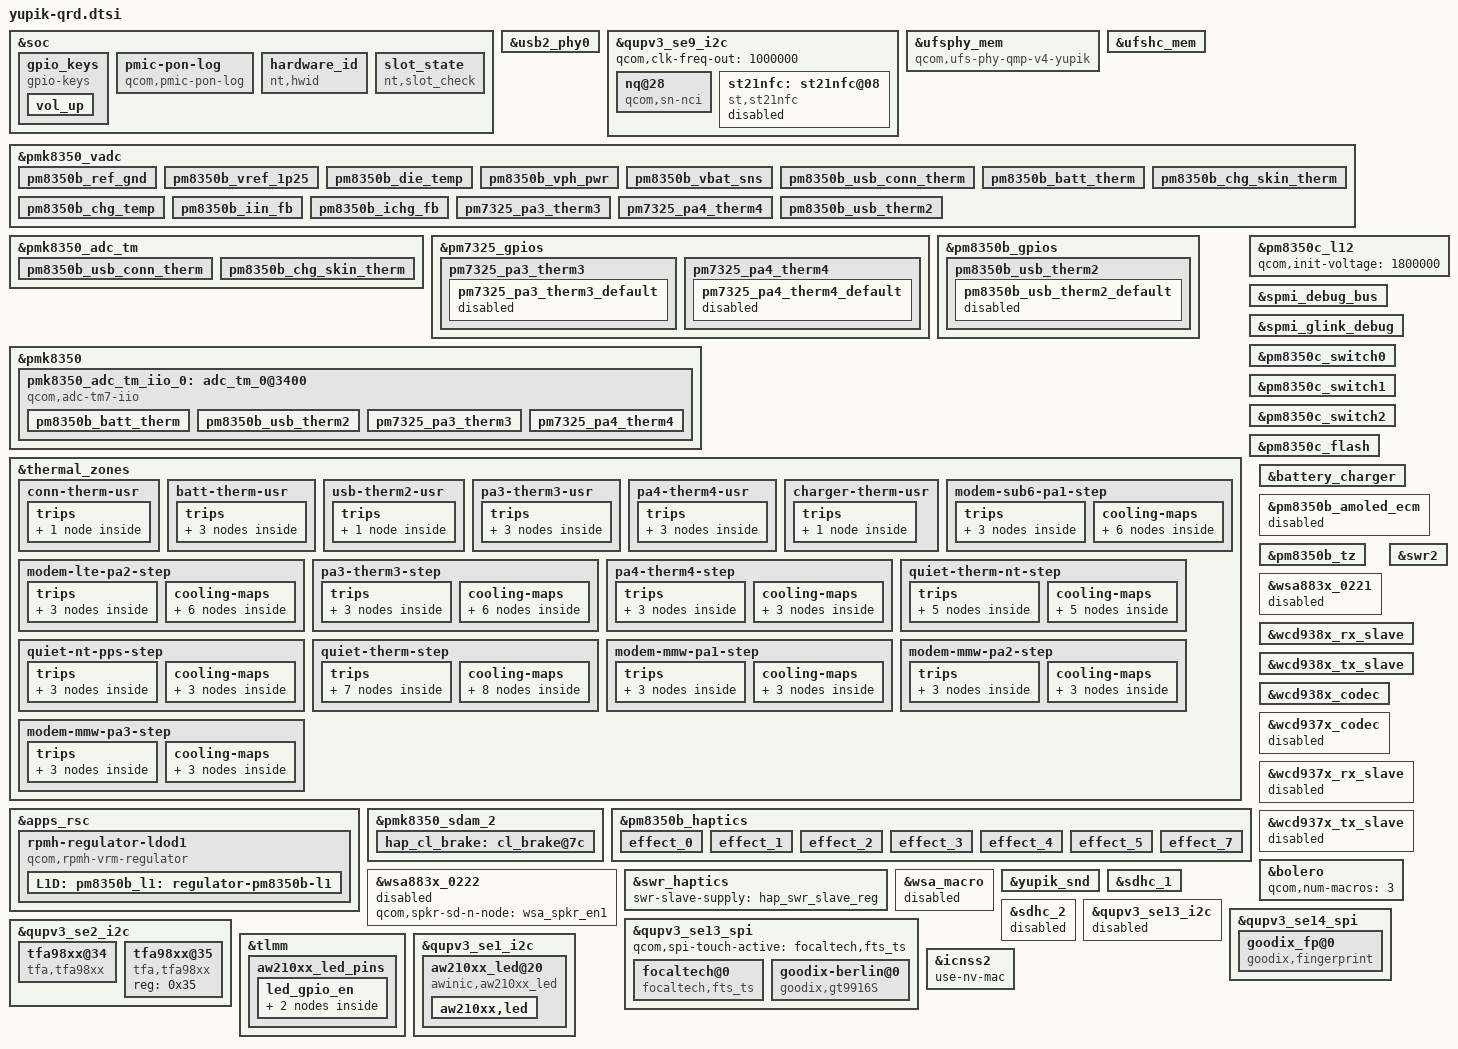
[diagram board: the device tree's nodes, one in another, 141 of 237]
#include <dt-bindings/gpio/gpio.h>
#include <dt-bindings/clock/qcom,rpmh.h>
#include <dt-bindings/regulator/qcom,rpmh-regulator-levels.h>
#include "yupik-pmic-overlay.dtsi"
#include "pm8350b.dtsi"
#include "yupik-audio-overlay.dtsi"
#include "yupik-thermal-overlay-qrd.dtsi"
#include "display/yupik-sde-display-qrd.dtsi"
//#include "camera/yupik-camera-sensor-qrd.dtsi"
#include "camera/abra-camera-sensor.dtsi"

&soc {
	gpio_keys {
		compatible = "gpio-keys";
		label = "gpio-keys";

		pinctrl-names = "default";
		pinctrl-0 = <&key_vol_up_default>;

		vol_up {
			label = "volume_up";
			gpios = <&pm7325_gpios 6 GPIO_ACTIVE_LOW>;
			linux,input-type = <1>;
			linux,code = <KEY_VOLUMEUP>;
			gpio-key,wakeup;
			debounce-interval = <15>;
			linux,can-disable;
		};
	};

	pmic-pon-log {
		compatible = "qcom,pmic-pon-log";
		nvmem = <&pmk8350_sdam_5>;
		nvmem-names = "pon_log";
	};
};

&usb2_phy0 {
	qcom,param-override-seq =
		<0xe6 0x6c	/* override_x0 */
		 0x0b 0x70	/* override_x1 */
		 0x14 0x74>;	/* override_x2 */
};

&qupv3_se9_i2c {
	status = "ok";
	qcom,clk-freq-out = <1000000>;
	#address-cells = <1>;
	#size-cells = <0>;
	nq@28 {
		compatible = "qcom,sn-nci";
		reg = <0x28>;
		qcom,sn-irq = <&tlmm 41 0x00>;
		qcom,sn-ven = <&tlmm 38 0x00>;
		qcom,sn-firm = <&tlmm 40 0x00>;
		qcom,sn-clkreq = <&tlmm 39 0x00>;
		qcom,sn-vdd-1p8-supply = <&L18B>;
		qcom,sn-vdd-1p8-voltage = <1800000 1800000>;
		qcom,sn-vdd-1p8-current = <157000>;
		interrupt-parent = <&tlmm>;
		interrupts = <41 0>;
		interrupt-names = "nfc_irq";
		pinctrl-names = "nfc_active", "nfc_suspend";
		pinctrl-0 = <&nfc_int_active &nfc_enable_active>;
		pinctrl-1 = <&nfc_int_suspend &nfc_enable_suspend>;
		status = "okay";
	};
};

&ufsphy_mem {
	compatible = "qcom,ufs-phy-qmp-v4-yupik";

	vdda-phy-supply = <&L10C>;
	vdda-pll-supply = <&L6B>;
	vdda-phy-max-microamp = <97500>;
	vdda-pll-max-microamp = <18400>;

	status = "ok";
};

&ufshc_mem {
	vdd-hba-supply = <&gcc_ufs_phy_gdsc>;
	vdd-hba-fixed-regulator;

	vcc-supply = <&L7B>;
	vcc-voltage-level = <2504000 2952000>;
	vcc-low-voltage-sup;
	vcc-max-microamp = <800000>;

	/*
	 * Yupik target supports both UFS2.2 & UFS3.1, here
	 * vccq2 is supplied via eLDO, and that is controlled via
	 * L9B which supports a max voltage of 1.2V, but eLDO would
	 * supply 1.8V. and same L9B acts as vccq voltage for UFS3.1
	 * devices.
	 * Here L9B can max support for 1.2V but UFS GKI driver code
	 * votes for 1.8V, which is leading to failure from pmic
	 * regulator.
	 *
	 * Now since vccq and control of eLDO are common that is L9B
	 * we can use vccq vote as control of eLDO for vccq2.
	 * Hence vccq entries shall be used for both type of UFS
	 * devices only. And vccq entries should not be changed/removed
	 * for any design alteration.
	 */
	vccq-supply = <&L9B>;
	vccq-max-microamp = <900000>;
	vccq-min-microamp = <10000>;

	qcom,vddp-ref-clk-supply = <&L9B>;
	qcom,vddp-ref-clk-max-microamp = <100>;

	status = "ok";
};

&pmk8350_vadc {
	pm8350b_ref_gnd {
		reg = <PM8350B_ADC7_REF_GND>;
		label = "pm8350b_ref_gnd";
		qcom,pre-scaling = <1 1>;
	};

	pm8350b_vref_1p25 {
		reg = <PM8350B_ADC7_1P25VREF>;
		label = "pm8350b_vref_1p25";
		qcom,pre-scaling = <1 1>;
	};

	pm8350b_die_temp {
		reg = <PM8350B_ADC7_DIE_TEMP>;
		label = "pm8350b_die_temp";
		qcom,pre-scaling = <1 1>;
	};

	pm8350b_vph_pwr {
		reg = <PM8350B_ADC7_VPH_PWR>;
		label = "pm8350b_vph_pwr";
		qcom,pre-scaling = <1 3>;
	};

	pm8350b_vbat_sns {
		reg = <PM8350B_ADC7_VBAT_SNS>;
		label = "pm8350b_vbat_sns";
		qcom,pre-scaling = <1 3>;
	};

	pm8350b_usb_conn_therm {
		reg = <PM8350B_ADC7_AMUX_THM4_100K_PU>;
		label = "pm8350b_usb_conn_therm";
		qcom,ratiometric;
		qcom,hw-settle-time = <200>;
		qcom,pre-scaling = <1 1>;
	};

	pm8350b_batt_therm {
		reg = <PM8350B_ADC7_AMUX_THM1_100K_PU>;
		label = "pm8350b_batt_therm";
		qcom,ratiometric;
		qcom,hw-settle-time = <200>;
		qcom,pre-scaling = <1 1>;
	};

	pm8350b_chg_skin_therm {
		reg = <PM8350B_ADC7_GPIO2_100K_PU>;
		label = "pm8350b_chg_skin_therm";
		qcom,ratiometric;
		qcom,hw-settle-time = <200>;
		qcom,pre-scaling = <1 1>;
	};

	pm8350b_chg_temp {
		reg = <PM8350B_ADC7_CHG_TEMP>;
		label = "pm8350b_chg_temp";
		qcom,pre-scaling = <1 1>;
	};

	pm8350b_iin_fb {
		reg = <PM8350B_ADC7_IIN_FB>;
		label = "pm8350b_iin_fb";
		qcom,pre-scaling = <32 100>;
	};

	pm8350b_ichg_fb {
		reg = <PM8350B_ADC7_ICHG_FB>;
		label = "pm8350b_ichg_fb";
		qcom,pre-scaling = <1000 305185>;
	};
};

&pmk8350_adc_tm {
	io-channels = <&pmk8350_vadc PM7325_ADC7_AMUX_THM1_100K_PU>,
			<&pmk8350_vadc PM7325_ADC7_AMUX_THM2_100K_PU>,
			<&pmk8350_vadc PM7325_ADC7_AMUX_THM3_100K_PU>,
			<&pmk8350_vadc PM7325_ADC7_AMUX_THM4_100K_PU>,
			<&pmk8350_vadc PMK8350_ADC7_AMUX_THM1_100K_PU>,
			<&pmk8350_vadc PM8350B_ADC7_AMUX_THM4_100K_PU>,
			<&pmk8350_vadc PM8350B_ADC7_GPIO2_100K_PU>;

	pm8350b_usb_conn_therm {
		reg = <PM8350B_ADC7_AMUX_THM4_100K_PU>;
		qcom,ratiometric;
		qcom,hw-settle-time = <200>;
	};

	pm8350b_chg_skin_therm {
		reg = <PM8350B_ADC7_GPIO2_100K_PU>;
		qcom,ratiometric;
		qcom,hw-settle-time = <200>;
	};
};

&pm7325_gpios {
	pm7325_pa3_therm3 {
		pm7325_pa3_therm3_default: pm7325_pa3_therm3_default {
			pins = "gpio2";
			function = "normal";
			bias-high-impedance;
			status = "disabled";
		};
	};
	pm7325_pa4_therm4 {
		pm7325_pa4_therm4_default: pm7325_pa4_therm4_default {
			pins = "gpio3";
			function = "normal";
			bias-high-impedance;
			status = "disabled";
		};
	};
};

&pm8350b_gpios {
	pm8350b_usb_therm2 {
		pm8350b_usb_therm2_default: pm8350b_usb_therm2_default {
			pins = "gpio3";
			function = "normal";
			bias-high-impedance;
			status = "disabled";
		};
	};
};

&pmk8350_vadc {
	pinctrl-names = "default";
	pinctrl-0 = <
	             &pm7325_pa3_therm3_default
	             &pm7325_pa4_therm4_default
	             &pm8350b_usb_therm2_default
	            >;
	pm7325_pa3_therm3 {
		reg = <PM7325_ADC7_GPIO1_100K_PU>;
		label = "pm7325_pa3_therm3";
		qcom,ratiometric;
		qcom,hw-settle-time = <200>;
		qcom,pre-scaling = <1 1>;
	};

	pm7325_pa4_therm4 {
		reg = <PM7325_ADC7_GPIO2_100K_PU>;
		label = "pm7325_pa4_therm4";
		qcom,ratiometric;
		qcom,hw-settle-time = <200>;
		qcom,pre-scaling = <1 1>;
	};

	pm8350b_usb_therm2 {
		reg = <PM8350B_ADC7_GPIO3_100K_PU>;
		label = "pm8350b_usb_therm2";
		qcom,ratiometric;
		qcom,hw-settle-time = <200>;
		qcom,pre-scaling = <1 1>;
	};
};

&pmk8350 {
	pmk8350_adc_tm_iio_0: adc_tm_0@3400 {
		compatible = "qcom,adc-tm7-iio";
		reg = <0x3400>;
		#thermal-sensor-cells = <1>;
		#address-cells = <1>;
		#size-cells = <0>;
		io-channels = <&pmk8350_vadc PM8350B_ADC7_AMUX_THM1_100K_PU>,
		<&pmk8350_vadc PM7325_ADC7_GPIO1_100K_PU>,
		<&pmk8350_vadc PM7325_ADC7_GPIO2_100K_PU>,
		<&pmk8350_vadc PM8350B_ADC7_GPIO3_100K_PU>;
		pm8350b_batt_therm {
			reg = <PM8350B_ADC7_AMUX_THM1_100K_PU>;
			qcom,ratiometric;
			qcom,hw-settle-time = <200>;
		};
		pm8350b_usb_therm2 {
			reg = <PM8350B_ADC7_GPIO3_100K_PU>;
			qcom,ratiometric;
			qcom,hw-settle-time = <200>;
		};
		pm7325_pa3_therm3 {
			reg = <PM7325_ADC7_GPIO1_100K_PU>;
			qcom,ratiometric;
			qcom,hw-settle-time = <200>;
		};
		pm7325_pa4_therm4 {
			reg = <PM7325_ADC7_GPIO2_100K_PU>;
			qcom,ratiometric;
			qcom,hw-settle-time = <200>;
		};
	};
};

&thermal_zones {
	conn-therm-usr {
		polling-delay-passive = <0>;
		polling-delay = <0>;
		thermal-governor = "user_space";
		thermal-sensors = <&pmk8350_adc_tm PM8350B_ADC7_AMUX_THM4_100K_PU>;
		wake-capable-sensor;
		trips {
			active-config0 {
				temperature = <125000>;
				hysteresis = <1000>;
				type = "passive";
			};
		};
	};

	batt-therm-usr {
		polling-delay-passive = <0>;
		polling-delay = <0>;
		thermal-governor = "user_space";
		thermal-sensors = <&pmk8350_adc_tm_iio_0 PM8350B_ADC7_AMUX_THM1_100K_PU>;
		wake-capable-sensor;
		trips {
			active-config0 {
				temperature = <40000>;
				hysteresis = <35000>;
				type = "passive";
			};
			active-config1 {
				temperature = <50000>;
				hysteresis = <45000>;
				type = "passive";
			};
			active-config2 {
				temperature = <60000>;
				hysteresis = <55000>;
				type = "passive";
			};
		};
	};

	usb-therm2-usr {
		polling-delay-passive = <0>;
		polling-delay = <0>;
		thermal-governor = "user_space";
		thermal-sensors = <&pmk8350_adc_tm_iio_0 PM8350B_ADC7_GPIO3_100K_PU>;
		wake-capable-sensor;
		trips {
			active-config0 {
				temperature = <125000>;
				hysteresis = <50000>;
				type = "passive";
			};
		};
	};

	pa3-therm3-usr {
		polling-delay-passive = <0>;
		polling-delay = <0>;
		thermal-governor = "user_space";
		thermal-sensors = <&pmk8350_adc_tm_iio_0 PM7325_ADC7_GPIO1_100K_PU>;
		wake-capable-sensor;
		trips {
			active-config0 {
				temperature = <80000>;
				hysteresis = <7000>;
				type = "passive";
			};
			active-config1 {
				temperature = <85000>;
				hysteresis = <7000>;
				type = "passive";
			};
			active-config2 {
				temperature = <86000>;
				hysteresis = <1000>;
				type = "passive";
			};
		};
	};

	pa4-therm4-usr {
		polling-delay-passive = <0>;
		polling-delay = <0>;
		thermal-governor = "user_space";
		thermal-sensors = <&pmk8350_adc_tm_iio_0 PM7325_ADC7_GPIO2_100K_PU>;
		wake-capable-sensor;
		trips {
			active-config0 {
				temperature = <80000>;
				hysteresis = <7000>;
				type = "passive";
			};
			active-config1 {
				temperature = <85000>;
				hysteresis = <7000>;
				type = "passive";
			};
			active-config2 {
				temperature = <86000>;
				hysteresis = <1000>;
				type = "passive";
			};
		};
	};

	charger-therm-usr {
		polling-delay-passive = <0>;
		polling-delay = <0>;
		thermal-governor = "user_space";
		thermal-sensors = <&pmk8350_adc_tm PM8350B_ADC7_GPIO2_100K_PU>;
		wake-capable-sensor;
		trips {
			active-config0 {
				temperature = <125000>;
				hysteresis = <1000>;
				type = "passive";
			};
		};
	};

	modem-sub6-pa1-step {
		polling-delay-passive = <0>;
		polling-delay = <0>;
		thermal-governor = "step_wise";
		thermal-sensors = <&qmi_sensor
				(QMI_MODEM_INST_ID+QMI_PA)>;
		trips {
			sub6_pa1_trip0: sub6-pa1-trip0 {
				temperature = <85000>;
				hysteresis = <7000>;
				type = "passive";
			};

			sub6_pa1_trip1: sub6-pa1-trip1 {
				temperature = <90000>;
				hysteresis = <7000>;
				type = "passive";
			};

			sub6_pa1_trip2: sub6-pa1-trip2 {
				temperature = <95000>;
				hysteresis = <1000>;
				type = "passive";
			};
		};

		cooling-maps {
			pa_cdev0 {
				trip = <&sub6_pa1_trip0>;
				cooling-device = <&modem_pa 1 1>;
			};

			pa_fr1_cdev0 {
				trip = <&sub6_pa1_trip0>;
				cooling-device = <&modem_pa_fr1 1 1>;
			};

			pa_cdev1 {
				trip = <&sub6_pa1_trip1>;
				cooling-device = <&modem_pa 2 2>;
			};

			pa_fr1_cdev1 {
				trip = <&sub6_pa1_trip1>;
				cooling-device = <&modem_pa_fr1 2 2>;
			};

			pa_cdev2 {
				trip = <&sub6_pa1_trip2>;
				cooling-device = <&modem_pa 3 3>;
			};

			pa_fr1_cdev2 {
				trip = <&sub6_pa1_trip2>;
				cooling-device = <&modem_pa_fr1 3 3>;
			};
		};
	};

	modem-lte-pa2-step {
		polling-delay-passive = <0>;
		polling-delay = <0>;
		thermal-governor = "step_wise";
		thermal-sensors = <&qmi_sensor
				(QMI_MODEM_INST_ID+QMI_PA_1)>;
		trips {
			lte_pa2_trip0: lte-pa2-trip0 {
				temperature = <85000>;
				hysteresis = <7000>;
				type = "passive";
			};

			lte_pa2_trip1: lte-pa2-trip1 {
				temperature = <90000>;
				hysteresis = <7000>;
				type = "passive";
			};

			lte_pa2_trip2: lte-pa2-trip2 {
				temperature = <95000>;
				hysteresis = <1000>;
				type = "passive";
			};
		};

		cooling-maps {
			pa_cdev0 {
				trip = <&lte_pa2_trip0>;
				cooling-device = <&modem_pa 1 1>;
			};

			pa_fr1_cdev0 {
				trip = <&lte_pa2_trip0>;
				cooling-device = <&modem_pa_fr1 1 1>;
			};

			pa_cdev1 {
				trip = <&lte_pa2_trip1>;
				cooling-device = <&modem_pa 2 2>;
			};

			pa_fr1_cdev1 {
				trip = <&lte_pa2_trip1>;
				cooling-device = <&modem_pa_fr1 2 2>;
			};

			pa_cdev2 {
				trip = <&lte_pa2_trip2>;
				cooling-device = <&modem_pa 3 3>;
			};

			pa_fr1_cdev2 {
				trip = <&lte_pa2_trip2>;
				cooling-device = <&modem_pa_fr1 3 3>;
			};
		};
	};

	pa3-therm3-step {
		polling-delay-passive = <0>;
		polling-delay = <0>;
		thermal-governor = "step_wise";
		thermal-sensors = <&pmk8350_adc_tm_iio_0 PM7325_ADC7_GPIO1_100K_PU>;
		wake-capable-sensor;
		trips {
			pa3_trip0: pa3_trip0 {
				temperature = <85000>;
				hysteresis = <7000>;
				type = "passive";
			};
			pa3_trip1: pa3_trip1 {
				temperature = <90000>;
				hysteresis = <7000>;
				type = "passive";
			};
			pa3_trip2: pa3_trip2 {
				temperature = <95000>;
				hysteresis = <1000>;
				type = "passive";
			};
		};
		cooling-maps {
			pa_cdev0 {
				trip = <&pa3_trip0>;
				cooling-device = <&modem_pa 1 1>;
			};

			pa_fr1_cdev0 {
				trip = <&pa3_trip0>;
				cooling-device = <&modem_pa_fr1 1 1>;
			};

			pa_cdev1 {
				trip = <&pa3_trip1>;
				cooling-device = <&modem_pa 2 2>;
			};

			pa_fr1_cdev1 {
				trip = <&pa3_trip1>;
				cooling-device = <&modem_pa_fr1 2 2>;
			};

			pa_cdev2 {
				trip = <&pa3_trip2>;
				cooling-device = <&modem_pa 3 3>;
			};

			pa_fr1_cdev2 {
				trip = <&pa3_trip2>;
				cooling-device = <&modem_pa_fr1 3 3>;
			};
		};
	};

	pa4-therm4-step {
		polling-delay-passive = <0>;
		polling-delay = <0>;
		thermal-governor = "step_wise";
		thermal-sensors = <&pmk8350_adc_tm_iio_0 PM7325_ADC7_GPIO2_100K_PU>;
		wake-capable-sensor;
		trips {
			pa4_trip0: pa4_trip0 {
				temperature = <85000>;
				hysteresis = <7000>;
				type = "passive";
			};
			pa4_trip1: pa4_trip1 {
				temperature = <90000>;
				hysteresis = <7000>;
				type = "passive";
			};
			pa4_trip2: pa4_trip2 {
				temperature = <95000>;
				hysteresis = <1000>;
				type = "passive";
			};
		};
		cooling-maps {
			pa_fr1_cdev0 {
				trip = <&pa4_trip0>;
				cooling-device = <&modem_pa_fr1 1 1>;
			};

			pa_fr1_cdev1 {
				trip = <&pa4_trip1>;
				cooling-device = <&modem_pa_fr1 2 2>;
			};

			pa_fr1_cdev2 {
				trip = <&pa4_trip2>;
				cooling-device = <&modem_pa_fr1 3 3>;
			};
		};
	};

	quiet-therm-nt-step {
		disable-thermal-zone;
		polling-delay-passive = <2000>;
		polling-delay = <0>;
		thermal-governor = "step_wise";
		thermal-sensors = <&pmk8350_adc_tm PM7325_ADC7_AMUX_THM1_100K_PU>;

		trips {
			quiet_batt_trip0: quiet-batt-trip0 {
				temperature = <38000>;
				hysteresis = <5000>;
				type = "passive";
			};

			quiet_batt_trip1: quiet-batt-trip1 {
				temperature = <40000>;
				hysteresis = <4000>;
				type = "passive";
			};

			quiet_batt_trip2: quiet-batt-trip2 {
				temperature = <42000>;
				hysteresis = <4000>;
				type = "passive";
			};

			quiet_batt_trip3: quiet-batt-trip3 {
				temperature = <45000>;
				hysteresis = <5000>;
				type = "passive";
			};

			quiet_batt_trip4: quiet-batt-trip4 {
				temperature = <53000>;
				hysteresis = <3000>;
				type = "passive";
			};
		};

		cooling-maps {
			batt-cdev0 {
				trip = <&quiet_batt_trip0>;
				cooling-device = <&battery_charger 2 2>;
			};

			batt-cdev1 {
				trip = <&quiet_batt_trip1>;
				cooling-device = <&battery_charger 3 3>;
			};

			batt-cdev2 {
				trip = <&quiet_batt_trip2>;
				cooling-device = <&battery_charger 4 4>;
			};

			batt-cdev3 {
				trip = <&quiet_batt_trip3>;
				cooling-device = <&battery_charger 6 6>;
			};

			batt-cdev4 {
				trip = <&quiet_batt_trip4>;
				cooling-device = <&battery_charger 7 7>;
			};
		};
	};

	quiet-nt-pps-step {
		polling-delay-passive = <2000>;
		polling-delay = <0>;
		thermal-governor = "step_wise";
		thermal-sensors = <&pmk8350_adc_tm PM7325_ADC7_AMUX_THM1_100K_PU>;

		trips {
			quiet_batt_pps_trip0: quiet-batt-pps-trip0 {
				temperature = <36000>;
				hysteresis = <3000>;
				type = "passive";
			};

			quiet_batt_pps_trip1: quiet-batt-pps-trip1 {
				temperature = <40000>;
				hysteresis = <5000>;
				type = "passive";
			};

			quiet_batt_pps_trip2: quiet-batt-pps-trip2 {
				temperature = <43000>;
				hysteresis = <4000>;
				type = "passive";
			};
		};

		cooling-maps {
			batt-pps-cdev0 {
				trip = <&quiet_batt_pps_trip0>;
				cooling-device = <&battery_charger 3 3>;
			};

			batt-pps-cdev1 {
				trip = <&quiet_batt_pps_trip1>;
				cooling-device = <&battery_charger 5 5>;
			};

			batt-pps-cdev2 {
				trip = <&quiet_batt_pps_trip2>;
				cooling-device = <&battery_charger 6 6>;
			};
		};
	};

	quiet-therm-step {
		polling-delay-passive = <2000>;
		polling-delay = <0>;
		thermal-governor = "step_wise";
		thermal-sensors = <&pmk8350_adc_tm PM7325_ADC7_AMUX_THM1_100K_PU>;

		trips {
			quiet_skin_trip0: quiet-skin-trip0 {
				temperature = <85000>;
				hysteresis = <4000>;
				type = "passive";
			};

			quiet_skin_trip1: quiet-skin-trip1 {
				temperature = <90000>;
				hysteresis = <4000>;
				type = "passive";
			};

			quiet_apc_trip: quiet-apc-trip {
				temperature = <50000>;
				hysteresis = <0>;
				type = "passive";
			};

			quiet_gpu_trip: quiet-gpu-trip {
				temperature = <52000>;
				hysteresis = <0>;
				type = "passive";
			};

			quiet_silver_trip: quiet-silver-trip {
				temperature = <55000>;
				hysteresis = <0>;
				type = "passive";
			};

			quiet_cx_trip: quiet-cx-trip {
				temperature = <55000>;
				hysteresis = <5000>;
				type = "passive";
			};

			quiet_skin_trip2: quiet-skin-trip2 {
				temperature = <95000>;
				hysteresis = <4000>;
				type = "passive";
			};
		};

		cooling-maps {
			apc_cluster_cdev:apc-cluster-cdev {
				trip = <&quiet_apc_trip>;
				cooling-device = <&apc1_cluster THERMAL_NO_LIMIT 5>;
			};

			cpu_silver_cdev:cpu-silver-cdev {
				trip = <&quiet_silver_trip>;
				/* throttle to 1516800KHz */
				cooling-device = <&CPU0 THERMAL_NO_LIMIT
						(THERMAL_MAX_LIMIT-6)>;
			};

			gpu-cdev_0 {
				trip = <&quiet_gpu_trip>;
				/* throttle to 555000000Hz */
				cooling-device = <&msm_gpu THERMAL_NO_LIMIT
						(THERMAL_MAX_LIMIT-2)>;
			};

			gpu-cdev_1 {
				trip = <&quiet_cx_trip>;
				/* throttle to 315000000Hz */
				cooling-device = <&msm_gpu THERMAL_MAX_LIMIT
						THERMAL_MAX_LIMIT>;
			};

			cdsp-cdev {
				trip = <&quiet_cx_trip>;
				cooling-device = <&cdsp_sw 4 4>;
			};

			skin-cdev0 {
				trip = <&quiet_skin_trip0>;
				cooling-device = <&modem_skin 1 1>;
			};

			skin-cdev1 {
				trip = <&quiet_skin_trip1>;
				cooling-device = <&modem_skin 2 2>;
			};

			skin-cdev2 {
				trip = <&quiet_skin_trip2>;
				cooling-device = <&modem_skin 3 3>;
			};
		};
	};

	modem-mmw-pa1-step {
		polling-delay-passive = <0>;
		polling-delay = <0>;
		thermal-governor = "step_wise";
		thermal-sensors = <&qmi_sensor
				(QMI_MODEM_INST_ID+QMI_MMW_PA1)>;
		trips {
			mmw_pa1_trip0: mmw-pa1-trip0 {
				temperature = <48000>;
				hysteresis = <2000>;
				type = "passive";
			};

			mmw_pa1_trip1: mmw-pa1-trip1 {
				temperature = <51000>;
				hysteresis = <2000>;
				type = "passive";
			};

			mmw_pa1_trip2: mmw-pa1-trip2 {
				temperature = <57000>;
				hysteresis = <4000>;
				type = "passive";
			};
		};

		cooling-maps {
			mmw_skin1_cdev0 {
				trip = <&mmw_pa1_trip0>;
				cooling-device = <&modem_mmw_skin1 1 1>;
			};

			mmw_skin1_cdev1 {
				trip = <&mmw_pa1_trip1>;
				cooling-device = <&modem_mmw_skin1 2 2>;
			};

			mmw_skin1_cdev2 {
				trip = <&mmw_pa1_trip2>;
				cooling-device = <&modem_mmw_skin1 3 3>;
			};
		};
	};

	modem-mmw-pa2-step {
		polling-delay-passive = <0>;
		polling-delay = <0>;
		thermal-governor = "step_wise";
		thermal-sensors = <&qmi_sensor
				(QMI_MODEM_INST_ID+QMI_MMW_PA2)>;
		trips {
			mmw_pa2_trip0: mmw-pa2-trip0 {
				temperature = <46000>;
				hysteresis = <2000>;
				type = "passive";
			};

			mmw_pa2_trip1: mmw-pa2-trip1 {
				temperature = <48000>;
				hysteresis = <2000>;
				type = "passive";
			};

			mmw_pa2_trip2: mmw-pa2-trip2 {
				temperature = <57000>;
				hysteresis = <4000>;
				type = "passive";
			};
		};

		cooling-maps {
			mmw_skin2_cdev0 {
				trip = <&mmw_pa2_trip0>;
				cooling-device = <&modem_mmw_skin2 1 1>;
			};

			mmw_skin2_cdev1 {
				trip = <&mmw_pa2_trip1>;
				cooling-device = <&modem_mmw_skin2 2 2>;
			};

			mmw_skin2_cdev2 {
				trip = <&mmw_pa2_trip2>;
				cooling-device = <&modem_mmw_skin2 3 3>;
			};
		};
	};

	modem-mmw-pa3-step {
		polling-delay-passive = <0>;
		polling-delay = <0>;
		thermal-governor = "step_wise";
		thermal-sensors = <&qmi_sensor
				(QMI_MODEM_INST_ID+QMI_MMW_PA3)>;
		trips {
			mmw_pa3_trip0: mmw-pa3-trip0 {
				temperature = <46000>;
				hysteresis = <2000>;
				type = "passive";
			};

			mmw_pa3_trip1: mmw-pa3-trip1 {
				temperature = <48000>;
				hysteresis = <2000>;
				type = "passive";
			};

			mmw_pa3_trip2: mmw-pa3-trip2 {
				temperature = <57000>;
				hysteresis = <4000>;
				type = "passive";
			};
		};

		cooling-maps {
			mmw_skin0_cdev0 {
				trip = <&mmw_pa3_trip0>;
				cooling-device = <&modem_mmw_skin0 1 1>;
			};

			mmw_skin0_cdev1 {
				trip = <&mmw_pa3_trip1>;
				cooling-device = <&modem_mmw_skin0 2 2>;
			};

			mmw_skin0_cdev2 {
				trip = <&mmw_pa3_trip2>;
				cooling-device = <&modem_mmw_skin0 3 3>;
			};
		};
	};
};

&apps_rsc {
	rpmh-regulator-ldod1 {
		compatible = "qcom,rpmh-vrm-regulator";
		qcom,resource-name = "ldod1";
		qcom,regulator-type = "pmic5-ldo";
		qcom,supported-modes =
			<RPMH_REGULATOR_MODE_LPM
			RPMH_REGULATOR_MODE_HPM>;
		qcom,mode-threshold-currents = <0 30000>;
		L1D:
		pm8350b_l1: regulator-pm8350b-l1 {
			regulator-name = "pm8350b_l1";
			qcom,set = <RPMH_REGULATOR_SET_ALL>;
			regulator-min-microvolt = <1100000>;
			regulator-max-microvolt = <1300000>;
			qcom,init-voltage = <1200000>;
			qcom,init-mode = <RPMH_REGULATOR_MODE_HPM>;
		};
	};
};

&pm8350c_l12 {
	qcom,init-voltage = <1800000>;
};

&spmi_debug_bus {
	status = "ok";
};

&spmi_glink_debug {
	status = "ok";
};

&pm8350c_switch0 {
	qcom,led-mask = <9>; /* Channels 1 & 4 */
	qcom,symmetry-en;
};

&pm8350c_switch1 {
	qcom,led-mask = <6>; /* Channels 2 & 3 */
	qcom,symmetry-en;
};

&pm8350c_switch2 {
	qcom,led-mask = <15>; /* All Channels */
	qcom,symmetry-en;
};

&pm8350c_flash {
	status = "ok";
};

&pmk8350_sdam_2 {
	hap_cl_brake: cl_brake@7c {
		reg = <0x7c 0x1>;
		bits = <0 8>;
	};
};

&pm8350b_haptics {
	nvmem-cell-names = "hap_cl_brake";
	nvmem-cells = <&hap_cl_brake>;
	nvmem-names = "hap_cfg_sdam";
	nvmem = <&pmk8350_sdam_46>;
	qcom,pbs-client = <&pm8350b_pbs2>;

	qcom,Vrms_mv = <1270>;
	qcom,vmax-mv = <1830>;  /* 9150 / 5 */
	qcom,lra-period-us = <4380>;
	status = "ok";

	effect_0 {
		/* CLICK */
		qcom,wf-vmax-mv = <9078>;
		qcom,wf-fifo-data = [
								01 01 01 01 02 03 03 04
								05 06 08 0a 0c 0f 13 18
								1e 25 2f 39 47 54 60 68
								6f 75 78 7b 7e 7f 7f 7f
								7e 7d 7c 7a 78 76 74 71
								6e 6b 68 65 62 5f 5c 59
								55 52 4f 4b 48 45 42 3f
								3b 37 34 31 2e 2a 27 23
								1e 1a 16 10 09 02 fa ef
								e2 d3 c3 b5 ab a2 9d 99
								96 95 94 95 97 99 9d a1
								a5 a9 ae b4 b9 bf c5 cb
								d1 d8 df e5 ec f3 f9 00
								06 0c 12 19 1f 25 2a 30
								35 3b 40 44 49 4d 51 55
								59 5c 5f 63 66 69 6d 71
								74 76 77 77 76 74 72 70
								6d 69 65 60 5b 56 51 4b
								45 3f 38 31 2b 24 1d 16
								0e 07 00 fa f3 ec e4 dd
								d6 d0 c9 c3 be b8 b3 ae
								a9 a4 9f 9c 98 95 93 90
								8f 8d 8c 8c 8c 8c 8d 8e
								90 91 94 96 99 9d a0 a5
								aa ae b3 b9 be c4 ca d1
								d7 dd e4 eb f1 f8 ff 06
								0d 13 1a 21 27 2e 34 3a
								40 45 4a 4f 54 58 5b 5e
								61 64 65 66 66 65 63 60
								5b 55 4f 49 44 40 3c 38
								34 31 2d 29 26 22 1e 1a
								16 11 0d 08 03 00 fb f5
								f0 eb e6 e0 db d6 d1 cc
								c8 c3 be ba b5 b1 ae aa
								a7 a4 a1 9f 9e 9d 9d 9e
								9f a2 a6 ac b4 bd ca d7
								e2 eb f2 f9 fe 01 05 09
								0c 0e 11 14 16 18 1a 1c
								1e 20 22 24 26 27 29 2b
								2d 2f 31 33 34 36 38 39
								3b 3c 3e 3f 40 41 42 43
								44 44 44 44 43 41 3f 3d
								39 35 2f 28 20 18 13 0e
								0b 08 06 05 03 03 02 02
								01 01 01 01 01 01 01 01
								01 01 01 01 02 02 02 02
								02 02 02 02 02 02 02 02
								02 02 02 02 02 02 02 02
								02 02 02 02 02 02 02 02
								02 02 02 02 02 02 02 02
								02 02 01 01 01 01 01 01
								01 01 01 01 01 01 01 01
								01 01 00 00 00 00 00 00
								00 00 00 00 00 00 00 00 ];
		qcom,lra-period-us = <5882>;
		qcom,wf-fifo-period = <S_PERIOD_F_24KHZ>;
	};

	effect_1 {
		/* DOUBLE_CLICK */
		qcom,wf-vmax-mv = <9078>;
		qcom,wf-fifo-data = [
								01 01 01 02 02 03 04 04
								06 07 09 0b 0e 11 15 1b
								21 29 33 3e 4b 54 5c 63
								66 69 6b 6c 6c 6b 6a 69
								66 63 60 5d 5a 57 53 4f
								4b 47 42 3d 39 35 30 2c
								27 23 1f 1b 16 12 0e 09
								05 00 fc f7 f1 eb e4 dc
								d3 c7 ba af a5 9f 9a 98
								97 96 98 9a 9e a2 a7 ac
								b2 b9 bf c7 ce d6 df e7
								ef f7 00 07 0f 18 20 28
								30 37 3f 46 4d 53 58 5e
								63 68 6c 70 73 76 79 7b
								7d 7e 7f 7f 7e 7c 7a 77
								73 6f 6a 65 60 59 53 4c
								44 3d 35 2d 25 1c 13 0b
								02 fb f3 ea e1 d9 d2 ca
								c3 bc b6 b0 ac a7 a3 a1
								9f 9e 9e a1 a5 ab b2 bd
								c9 d3 db e3 e9 ee f3 f8
								fd 00 05 09 0d 12 16 1a
								1e 22 27 2b 30 34 38 3d
								41 45 49 4d 51 55 58 5c
								5f 61 64 66 67 68 68 67
								65 62 5f 59 51 48 3b 30
								27 20 1a 15 11 0e 0b 09
								08 06 06 05 04 04 04 03
								03 03 03 03 03 03 02 02
								02 02 02 02 02 02 02 02
								02 02 02 02 02 02 02 02
								02 02 02 02 02 02 02 02
								01 01 01 01 01 01 01 01
								01 01 01 01 01 01 01 00
								00 00 00 00 00 00 00 00
								00 00 00 00 00 00 00 00
								00 00 00 00 00 00 00 00
								00 00 00 00 00 00 00 00
								00 00 00 00 00 00 00 00
								00 00 00 00 00 00 00 00
								00 00 00 00 00 00 00 00
								00 00 00 00 00 00 00 00
								00 00 00 00 00 00 00 00
								00 00 00 00 00 00 00 00
								00 00 00 00 00 00 00 00
								00 00 00 00 00 00 00 00
								00 00 00 00 00 00 00 00
								00 00 00 00 00 00 00 00
								00 00 00 00 00 00 00 00
								00 00 00 00 00 00 00 00
								00 00 00 00 00 00 00 00
								00 00 00 00 00 00 00 00
								00 00 00 00 00 00 00 00
								00 00 00 00 00 00 00 00
								00 00 00 00 00 00 00 00
								00 00 00 00 00 00 00 00
								00 00 00 00 00 00 00 00
								00 00 00 00 00 00 00 00
								00 00 00 00 00 00 00 00
								00 00 00 00 00 00 00 00
								00 00 00 00 00 00 00 00
								00 00 00 00 00 00 00 00
								00 00 00 00 00 00 00 00
								00 00 00 00 00 00 00 00
								00 00 00 00 00 00 00 00
								00 00 00 00 00 00 00 00
								00 00 00 00 00 00 00 00
								00 00 00 00 00 00 00 00
								00 00 00 00 00 00 00 00
								00 00 00 00 00 00 00 00
								00 00 00 00 00 00 00 00
								00 00 00 00 00 00 00 00
								00 00 00 00 00 00 00 00
								00 00 00 00 00 00 00 00
								00 00 00 00 00 00 00 00
								00 00 00 00 00 00 00 00
								00 00 00 00 00 00 00 00
								00 00 00 00 00 00 00 00
								00 00 00 00 00 00 00 00
								00 00 00 00 00 00 00 00 ];
		qcom,lra-period-us = <5882>;
		qcom,wf-fifo-period = <S_PERIOD_F_24KHZ>;
	};

	effect_2 {
		/* TICK */
		qcom,effect-id = <2>;
		qcom,wf-vmax-mv = <9078>;
		qcom,wf-fifo-data = [
								01 01 01 02 02 03 03 04
								05 06 08 0a 0d 10 13 18
								1e 25 2d 34 38 3c 40 43
								46 48 4a 4b 4d 4e 4f 50
								51 52 53 54 55 56 57 58
								59 5a 5b 5c 5d 5e 5f 60
								61 62 63 64 65 66 68 69
								6a 6b 6c 6d 6e 6f 70 71
								72 73 74 75 76 77 78 79
								7a 7b 7c 7c 7d 7e 7e 7f
								7f 7f 7f 7f 7f 7e 7c 7b
								79 77 73 70 6b 65 5d 53
								47 3a 30 27 20 1b 16 11
								0d 0a 07 04 02 00 fe fc
								fa f8 f5 f3 f1 ef ec ea
								e7 e5 e3 e0 de db d8 d6
								d3 d0 cd cb c8 c5 c2 bf
								bd ba b7 b4 b2 af ac a9
								a6 a4 a1 9f 9c 9a 98 96
								93 91 8f 8e 8c 8a 88 87
								86 85 84 83 82 81 81 81
								81 82 83 86 89 8d 91 96
								9c a1 a6 a9 ad af b2 b4
								b7 b9 bb bd bf c1 c4 c6
								c8 ca cd cf d2 d5 d7 db
								de e1 e4 e7 ea ed f0 f3
								f7 fa fd 00 03 07 0a 0e
								11 14 18 1b 1e 21 25 28
								2b 2e 31 35 38 3b 3d 40
								43 45 47 4a 4c 4e 50 52
								54 56 58 5a 5b 5d 5f 60
								62 64 65 67 6a 6c 6f 73
								75 77 78 79 79 79 79 78
								78 77 76 75 73 72 71 6f
								6e 6c 6a 68 66 64 62 60
								5e 5b 59 57 54 51 4f 4c
								4a 47 45 42 3f 3d 3a 38
								35 32 2f 2d 2a 28 25 23
								21 1e 1c 1a 17 15 13 11
								0f 0d 0b 09 07 05 03 01
								00 ff fc fa f8 f5 f2 ef
								eb e6 e1 da d2 c9 bf b8
								b1 ac a8 a5 a2 a0 9f 9d
								9d 9c 9c 9c 9c 9c 9c 9d
								9d 9e 9e 9f a0 a0 a1 a2
								a3 a4 a4 a5 a6 a7 a8 a9
								aa ab ab ac ad ae af b0
								b1 b2 b3 b4 b5 b5 b6 b7
								b8 b9 ba ba bb bc bd bd
								be bf c0 c0 c1 c2 c3 c3
								c4 c5 c7 c8 c9 cb cd cf
								d2 d5 da df e5 eb ef f3
								f6 f8 fa fc fd fe ff ff
								ff 00 00 00 00 00 00 00
								00 00 00 00 00 00 00 00
								ff ff ff ff ff ff ff ff
								ff ff ff ff ff ff fe fe
								fe fe fe fe fe fe fe fe
								fe fe fe fe fe fe fe fe
								fe fe fe fe fe fe fe ff
								00 00 00 00 00 00 00 00
								00 00 00 00 00 00 00 00
								00 00 00 00 00 00 00 00 ];
		qcom,lra-period-us = <5882>;
		qcom,wf-fifo-period = <S_PERIOD_F_24KHZ>;
	};

	effect_3 {
		/* THUD */
		qcom,wf-vmax-mv = <9078>;
		qcom,wf-fifo-data = [
								01 01 01 02 02 03 03 04
								05 07 09 0b 0d 10 14 1a
								20 27 31 3c 49 52 5a 61
								66 6a 6d 70 72 73 74 75
								76 76 76 76 76 75 75 74
								74 73 72 72 71 70 6f 6e
								6e 6d 6c 6b 6a 69 68 67
								66 65 64 63 62 61 60 5f
								5e 5d 5b 5a 58 56 54 51
								4e 4a 46 41 3a 32 29 1d
								0f ff e9 d2 c0 b0 a4 9a
								93 8d 89 85 83 81 81 81
								81 81 81 82 84 85 86 88
								8a 8c 8e 90 92 94 97 99
								9b 9e a0 a3 a5 a8 aa ac
								af b1 b3 b6 b8 ba bc be
								c1 c4 c6 c8 ca cc cf d1
								d4 d7 db df e4 e9 f0 f8
								00 0b 17 22 2a 31 36 39
								3c 3e 3f 40 40 40 3f 3e
								3c 3a 39 37 34 32 30 2d
								2a 27 25 21 1e 1b 18 15
								11 0e 0b 08 05 02 00 fd
								fa f7 f5 f2 ef ed ea e8
								e6 e4 e2 e0 df de dd dc
								dc dc dd de e0 e3 e6 eb
								f1 f7 fd 01 05 09 0c 0f
								11 14 16 18 1a 1c 1e 20
								22 24 26 28 2a 2c 2f 31
								33 36 38 3a 3d 3f 42 44
								46 49 4b 4e 50 52 55 57
								59 5b 5d 5f 60 62 63 66
								67 67 68 68 67 66 65 62
								60 5c 57 4f 47 3c 2e 1d
								0a f9 eb df d6 ce c8 c2
								be bb b8 b5 b3 b1 af ae
								ac ab aa a9 a7 a6 a5 a4
								a3 a3 a2 a1 a0 9f 9e 9d
								9c 9b 9a 9a 99 98 97 96
								96 95 94 94 93 93 92 92
								92 92 92 92 93 94 96 98
								9a 9d a1 a6 ac b3 bd c8
								d2 da e0 e6 ea ef f2 f4
								f6 f8 f9 fa fb fc fc fd
								fd fe fe fe ff ff ff ff
								ff 00 00 00 00 00 00 00
								00 00 00 00 01 01 01 01
								01 01 01 01 01 01 01 01
								01 01 01 01 01 01 01 01
								01 01 01 01 01 01 01 01
								01 01 01 00 00 00 00 00
								00 00 00 00 00 00 00 00
								00 00 00 00 00 00 00 00
								00 00 00 00 00 00 00 00 ];
		qcom,lra-period-us = <5882>;
		qcom,wf-fifo-period = <S_PERIOD_F_24KHZ>;
	};

	effect_4 {
		/* POP */
		qcom,wf-vmax-mv = <9078>;
		qcom,wf-fifo-data = [
								01 01 01 01 02 03 03 04
								05 06 08 0a 0c 0f 13 18
								1e 25 2f 39 47 54 60 68
								6f 75 78 7b 7e 7f 7f 7f
								7e 7d 7c 7a 78 76 74 71
								6e 6b 68 65 62 5f 5c 59
								55 52 4f 4b 48 45 42 3f
								3b 37 34 31 2e 2a 27 23
								1e 1a 16 10 09 02 fa ef
								e2 d3 c3 b5 ab a2 9d 99
								96 95 94 95 97 99 9d a1
								a5 a9 ae b4 b9 bf c5 cb
								d1 d8 df e5 ec f3 f9 00
								06 0c 12 19 1f 25 2a 30
								35 3b 40 44 49 4d 51 55
								59 5c 5f 63 66 69 6d 71
								74 76 77 77 76 74 72 70
								6d 69 65 60 5b 56 51 4b
								45 3f 38 31 2b 24 1d 16
								0e 07 00 fa f3 ec e4 dd
								d6 d0 c9 c3 be b8 b3 ae
								a9 a4 9f 9c 98 95 93 90
								8f 8d 8c 8c 8c 8c 8d 8e
								90 91 94 96 99 9d a0 a5
								aa ae b3 b9 be c4 ca d1
								d7 dd e4 eb f1 f8 ff 06
								0d 13 1a 21 27 2e 34 3a
								40 45 4a 4f 54 58 5b 5e
								61 64 65 66 66 65 63 60
								5b 55 4f 49 44 40 3c 38
								34 31 2d 29 26 22 1e 1a
								16 11 0d 08 03 00 fb f5
								f0 eb e6 e0 db d6 d1 cc
								c8 c3 be ba b5 b1 ae aa
								a7 a4 a1 9f 9e 9d 9d 9e
								9f a2 a6 ac b4 bd ca d7
								e2 eb f2 f9 fe 01 05 09
								0c 0e 11 14 16 18 1a 1c
								1e 20 22 24 26 27 29 2b
								2d 2f 31 33 34 36 38 39
								3b 3c 3e 3f 40 41 42 43
								44 44 44 44 43 41 3f 3d
								39 35 2f 28 20 18 13 0e
								0b 08 06 05 03 03 02 02
								01 01 01 01 01 01 01 01
								01 01 01 01 02 02 02 02
								02 02 02 02 02 02 02 02
								02 02 02 02 02 02 02 02
								02 02 02 02 02 02 02 02
								02 02 02 02 02 02 02 02
								02 02 01 01 01 01 01 01
								01 01 01 01 01 01 01 01
								01 01 00 00 00 00 00 00
								00 00 00 00 00 00 00 00 ];
		qcom,lra-period-us = <5882>;
		qcom,wf-fifo-period = <S_PERIOD_F_24KHZ>;
	};

	effect_5 {
		/* HEAVY CLICK */
		qcom,wf-vmax-mv = <9078>;
		qcom,wf-fifo-data = [
								01 01 01 02 02 03 03 04
								05 07 09 0b 0d 10 14 1a
								20 27 31 3c 49 52 5a 61
								66 6a 6d 70 72 73 74 75
								76 76 76 76 76 75 75 74
								74 73 72 72 71 70 6f 6e
								6e 6d 6c 6b 6a 69 68 67
								66 65 64 63 62 61 60 5f
								5e 5d 5b 5a 58 56 54 51
								4e 4a 46 41 3a 32 29 1d
								0f ff e9 d2 c0 b0 a4 9a
								93 8d 89 85 83 81 81 81
								81 81 81 82 84 85 86 88
								8a 8c 8e 90 92 94 97 99
								9b 9e a0 a3 a5 a8 aa ac
								af b1 b3 b6 b8 ba bc be
								c1 c4 c6 c8 ca cc cf d1
								d4 d7 db df e4 e9 f0 f8
								00 0b 17 22 2a 31 36 39
								3c 3e 3f 40 40 40 3f 3e
								3c 3a 39 37 34 32 30 2d
								2a 27 25 21 1e 1b 18 15
								11 0e 0b 08 05 02 00 fd
								fa f7 f5 f2 ef ed ea e8
								e6 e4 e2 e0 df de dd dc
								dc dc dd de e0 e3 e6 eb
								f1 f7 fd 01 05 09 0c 0f
								11 14 16 18 1a 1c 1e 20
								22 24 26 28 2a 2c 2f 31
								33 36 38 3a 3d 3f 42 44
								46 49 4b 4e 50 52 55 57
								59 5b 5d 5f 60 62 63 66
								67 67 68 68 67 66 65 62
								60 5c 57 4f 47 3c 2e 1d
								0a f9 eb df d6 ce c8 c2
								be bb b8 b5 b3 b1 af ae
								ac ab aa a9 a7 a6 a5 a4
								a3 a3 a2 a1 a0 9f 9e 9d
								9c 9b 9a 9a 99 98 97 96
								96 95 94 94 93 93 92 92
								92 92 92 92 93 94 96 98
								9a 9d a1 a6 ac b3 bd c8
								d2 da e0 e6 ea ef f2 f4
								f6 f8 f9 fa fb fc fc fd
								fd fe fe fe ff ff ff ff
								ff 00 00 00 00 00 00 00
								00 00 00 00 01 01 01 01
								01 01 01 01 01 01 01 01
								01 01 01 01 01 01 01 01
								01 01 01 01 01 01 01 01
								01 01 01 00 00 00 00 00
								00 00 00 00 00 00 00 00
								00 00 00 00 00 00 00 00
								00 00 00 00 00 00 00 00 ];
		qcom,lra-period-us = <5882>;
		qcom,wf-fifo-period = <S_PERIOD_F_24KHZ>;
	};

	effect_7 {
		/* FIFO sample only */
		qcom,wf-vmax-mv = <1830>;
		qcom,wf-pattern-period-us = <5880>;
	};
};

&battery_charger {
	qcom,thermal-mitigation = <6500000 5000000 4000000 3000000 2500000
				2000000 0>;
};

&pm8350b_amoled_ecm {
	status = "disabled";
	display-panels = <&dsi_r66451_amoled_90hz_cmd_cphy
			&dsi_r66451_amoled_144hz_cmd_cphy>;
};

&pm8350b_tz {
	io-channels = <&pmk8350_vadc PM8350B_ADC7_DIE_TEMP>;
	io-channel-names = "thermal";
};

&wsa883x_0221 {
	status = "disabled";
};

&wsa883x_0222 {
	qcom,spkr-sd-n-node = <&wsa_spkr_en1>;
	status = "disabled";
};

&swr_haptics {
	status = "okay";
	swr-slave-supply = <&hap_swr_slave_reg>;
};

&swr2 {
	qcom,swr-phy-dev-addr = <0x0D 0x01170223>,
				<0x08 0x58350223>,
				<0x08 0x58350222>,
				<0x08 0x58350221>,
				<0x08 0x58350220>;
};

&wcd938x_rx_slave {
	status = "okay";
};

&wcd938x_tx_slave {
	status = "okay";
};

&wcd938x_codec {
	status = "okay";
};

&wcd937x_codec {
	status = "disabled";
};

&wcd937x_rx_slave {
	status = "disabled";
};

&wcd937x_tx_slave {
	status = "disabled";
};


&bolero {
	qcom,num-macros = <3>;
};

&wsa_macro {
	status = "disabled";
};

&yupik_snd {
	qcom,model = "lahaina-yupikqrd-snd-card";
	qcom,audio-routing =
		"AMIC1", "Analog Mic1",
		"Analog Mic1", "MIC BIAS1",
		"AMIC2", "Analog Mic2",
		"Analog Mic2", "MIC BIAS2",
		"AMIC3", "Analog Mic3",
		"Analog Mic3", "MIC BIAS3",
		"AMIC4", "Analog Mic4",
		"Analog Mic4", "MIC BIAS1",
		"AMIC5", "Analog Mic5",
		"Analog Mic5", "MIC BIAS4",
		"TX DMIC0", "Digital Mic0",
		"Digital Mic0", "MIC BIAS1",
		"TX DMIC1", "Digital Mic1",
		"Digital Mic1", "MIC BIAS1",
		"TX DMIC2", "Digital Mic2",
		"Digital Mic2", "MIC BIAS3",
		"TX DMIC3", "Digital Mic3",
		"Digital Mic3", "MIC BIAS3",
		"TX DMIC4", "Digital Mic4",
		"Digital Mic4", "MIC BIAS4",
		"TX DMIC5", "Digital Mic5",
		"Digital Mic5", "MIC BIAS4",
		"IN1_HPHL", "HPHL_OUT",
		"IN2_HPHR", "HPHR_OUT",
		"IN3_AUX", "AUX_OUT",
		"HAP_IN", "PCM_OUT",
		"RX_TX DEC0_INP", "TX DEC0 MUX",
		"RX_TX DEC1_INP", "TX DEC1 MUX",
		"RX_TX DEC2_INP", "TX DEC2 MUX",
		"RX_TX DEC3_INP", "TX DEC3 MUX",
		"TX SWR_INPUT", "WCD_TX_OUTPUT",
		"VA SWR_INPUT", "VA_SWR_CLK",
		"VA SWR_INPUT", "WCD_TX_OUTPUT",
		"VA_AIF1 CAP", "VA_SWR_CLK",
		"VA_AIF2 CAP", "VA_SWR_CLK",
		"VA_AIF3 CAP", "VA_SWR_CLK",
		"VA DMIC0", "Digital Mic0",
		"VA DMIC1", "Digital Mic1",
		"VA DMIC2", "Digital Mic2",
		"VA DMIC3", "Digital Mic3",
		"VA DMIC4", "Digital Mic4",
		"VA DMIC5", "Digital Mic5",
		"VA DMIC0", "VA MIC BIAS1",
		"VA DMIC1", "VA MIC BIAS3",
		"VA DMIC2", "VA MIC BIAS4",
		"VA DMIC3", "VA MIC BIAS1",
		"VA DMIC4", "VA MIC BIAS3",
		"VA DMIC5", "VA MIC BIAS4";
	qcom,swr-dmic-max-devs = <0>;

	qcom,msm-mbhc-usbc-audio-supported = <1>;
	qcom,msm-mbhc-hphl-swh = <0>;
	qcom,msm-mbhc-gnd-swh = <0>;

	asoc-codec  = <&stub_codec>, <&bolero>,
		      <&wcd938x_codec>, <&swr_haptics>,
		      <&ext_disp_audio_codec>;
	asoc-codec-names = "msm-stub-codec.1", "bolero_codec",
			   "wcd938x_codec", "swr-haptics",
			   "msm-ext-disp-audio-codec-rx";
	qcom,wsa-max-devs = <0>;
	qcom,msm_audio_ssr_devs = <&audio_apr>, <&q6core>, <&lpi_tlmm>,
				  <&bolero>;
};

&sdhc_1 {
	pinctrl-names = "default", "sleep";
	pinctrl-0 = <&sdc1_on>;
	pinctrl-1 = <&sdc1_off>;

	vdd-supply = <&L7B>;
	qcom,vdd-voltage-level = <2952000 2952000>;
	qcom,vdd-current-level = <0 570000>;

	vdd-io-supply = <&L19B>;
	qcom,vdd-io-always-on;
	qcom,vdd-io-lpm-sup;
	qcom,vdd-io-voltage-level = <1800000 1800000>;
	qcom,vdd-io-current-level = <0 325000>;

	status = "ok";
};

&sdhc_2 {
	pinctrl-names = "default", "sleep";
	pinctrl-0 = <&sdc2_on>;
	pinctrl-1 = <&sdc2_off>;

	vdd-supply = <&L9C>;
	qcom,vdd-voltage-level = <2960000 2960000>;
	qcom,vdd-current-level = <0 800000>;

	vdd-io-supply = <&L6C>;
	qcom,vdd-io-voltage-level = <1800000 2960000>;
	qcom,vdd-io-current-level = <0 22000>;

	cd-gpios = <&tlmm 91 GPIO_ACTIVE_LOW>;

	status = "disabled";
};

&qupv3_se13_i2c {
	status = "disabled";
};

&qupv3_se13_spi {
	status = "ok";
	qcom,spi-touch-active = "focaltech,fts_ts";

	focaltech@0 {
		status = "okay";
		compatible = "focaltech,fts_ts";
		reg = <0x0>;
		spi-max-frequency = <6000000>;
		interrupt-parent = <&tlmm>;
		interrupts = <81 0x2008>;
		focaltech,reset-gpio = <&tlmm 105 0x00>;
		focaltech,irq-gpio = <&tlmm 81 0x2008>;
		focaltech,display-coords = <0 0 1080 2400>;
		focaltech,max-touch-number = <10>;
		focaltech,ic-type = <0x3658D488>;

		vdd-supply = <&L3C>;
		iovdd-supply = <&L8C>;

		pinctrl-names = "pmx_ts_active", "pmx_ts_suspend","pmx_ts_release";
		pinctrl-0 = <&ts_active>;
		pinctrl-1 = <&ts_int_suspend &ts_reset_suspend>;
		pinctrl-2 = <&ts_release>;
		focaltech,trusted-touch-mode = "vm_mode";
		focaltech,touch-environment = "pvm";
		focaltech,trusted-touch-spi-irq = <601>;
		focaltech,trusted-touch-io-bases = <0xf134000 0xf135000 0xf136000 0xf137000 0xf169000 0xf151000 0xa94000 0x00a10000>;
		focaltech,trusted-touch-io-sizes = <0x1000 0x1000 0x1000 0x1000 0x1000 0x1000 0x1000 0x4000>;
		panel = <&dsi_rm692e5_visionox_amoled_120hz_cmd>;
	};

	goodix-berlin@0 {
		compatible = "goodix,gt9916S";
		reg = <0>;
		spi-max-frequency = <1000000>;

		goodix,avdd-name = "avdd";
		avdd-supply = <&L3C>;
		goodix,iovdd-name = "iovdd";
		iovdd-supply = <&L8C>;

		goodix,reset-gpio = <&tlmm 105 0x0>;
		goodix,irq-gpio = <&tlmm 81 0x2800>;
		goodix,irq-flags = <2>; /* 1:trigger rising, 2:trigger falling;*/
		goodix,panel-max-x = <1080>;
		goodix,panel-max-y = <2400>;
		goodix,panel-max-w = <255>;
		goodix,panel-max-p = <4096>; /* max pressure that pen device supported */
		goodix,pen-enable; /* support active stylus device*/

		goodix,firmware-name = "goodix_firmware.bin";
		goodix,config-name = "goodix_cfg_group.bin";
	};
};

&qupv3_se9_i2c {
    status = "okay";
    st21nfc: st21nfc@08 {
        compatible = "st,st21nfc";
        reg = <0x08>;
        interrupt-parent = <&tlmm>;
        interrupts = <41  0>;
        reset-gpios = <&tlmm 38 0x00>;
        irq-gpios = <&tlmm 41 0x00>;
        // pidle-gpios = <&tlmm 48 0x00>;
        clkreq-gpios = <&tlmm 39 0x00>;
        clocks = <&rpmhcc RPMH_LN_BB_CLK2>;
        clock-names = "nfc_ref_clk";
        st,clk_pinctrl;
        status = "disabled";
    };
};

&qupv3_se14_spi {
	status = "okay";
	goodix_fp@0 {
		compatible = "goodix,fingerprint";
		reg = <0>;
		spi-max-frequency = <6000000>;
		interrupt-parent = <&tlmm>;
		fp-gpio-power = <&tlmm 2 0x00>;
		fp-gpio-irq = <&tlmm 34 0x00>;
		fp-gpio-reset = <&tlmm 61 0x00>;
		panel = <&dsi_rm692e5_visionox_amoled_120hz_cmd>;
		status = "okay";
	};

};

&qupv3_se2_i2c {
	status = "okay";
	tfa98xx@34 {
		compatible = "tfa,tfa98xx";
		reg = <0x34>;
		reset-gpio = <&tlmm 101 0>;
	};

	tfa98xx@35 {
		compatible = "tfa,tfa98xx";
		reg = <0x35>;
	};
};
&tlmm{
	aw210xx_led_pins {
		led_gpio_en: led_gpio_en {
			mux {
				pins = "gpio18";
				function = "gpio";
			};

			config {
				pins = "gpio18";
				drive-strength = <2>;
				output-high;
				bias-pull-up;
			};
		};
	};
};

&qupv3_se1_i2c {
	status = "ok";
	aw210xx_led@20 {
		compatible = "awinic,aw210xx_led";
		reg = <0x20>;
		enable-gpio = <&tlmm 18 0x00>;
		global_current = <0x20>;
		osc_clk = <1>;
		br_res = <3>;
		pinctrl-names = "default";
		pinctrl-0 = <&led_gpio_en>;
		status = "ok";
		aw210xx,led {
			aw210xx,name = "aw210xx_led";
			aw210xx,imax = <1>;
			aw210xx,brightness = <4095>;
			aw210xx,max_brightness = <4095>;
			};
		};
};

&qupv3_se1_i2c {
	/delete-node/ nq@64;
};

&soc {
	hardware_id {
		compatible = "nt,hwid";
		gpio_id1 = <&tlmm 19 0x00>;
		gpio_id2 = <&tlmm 21 0x00>;
	};

	slot_state {
		compatible = "nt,slot_check";
		gpio112 = <&tlmm 112 0x00>;
		gpio116 = <&tlmm 116 0x00>;
	};
};

&icnss2 {
	use-nv-mac;
};
